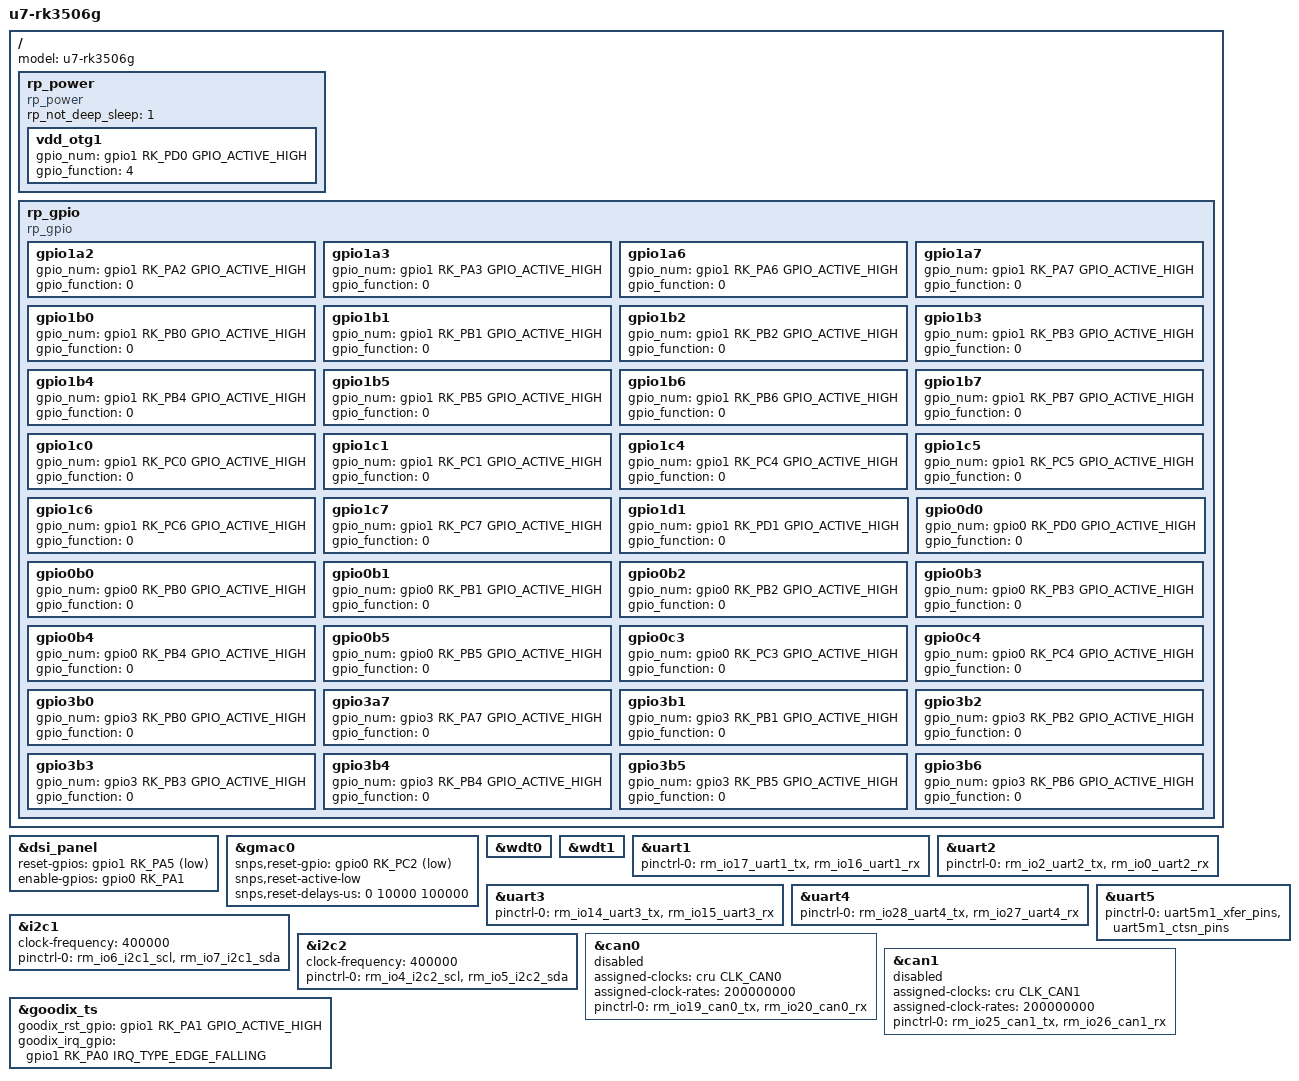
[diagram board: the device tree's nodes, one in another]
// SPDX-License-Identifier: (GPL-2.0+ OR MIT)
/*
 * Copyright (c) 2024 Rockchip Electronics Co., Ltd.
 */

/dts-v1/;
#include <dt-bindings/gpio/nca9555-gpio.h>

#include "rp-rk3506b-board.dtsi"

#include "rp-adc.dtsi"

#include "rp-usb2.0-otg0-typeA.dtsi"
#include "rp-usb2.0-host1-typeA.dtsi"

#include "rp-gmac0-100m.dtsi"
#include "rp-sdcard-mmc0.dtsi"

//#include "rp-lcd-mipi-7-1024-600.dtsi"
#include "rp-lcd-mipi-7-1024-600-lcdm012.dtsi"
//#include "rp-lcd-mipi0-8-800-1280-lcdm028T.dtsi"
// #include "rp-lcd-mipi0-10-800-1280-lcdm036J.dtsi"

/ {
    model = "u7-rk3506g";
	
    rp_power {
        status = "okay";
        compatible = "rp_power";
        rp_not_deep_sleep = <1>;

//#define GPIO_FUNCTION_OUTPUT 0
//#define GPIO_FUNCTION_INPUT 1
//#define GPIO_FUNCTION_IRQ 2
//#define GPIO_FUNCTION_FLASH 3
//#define GPIO_FUNCTION_OUTPUT_CTRL 4
        vdd_otg1 {
            gpio_num = <&gpio1 RK_PD0 GPIO_ACTIVE_HIGH>;
            gpio_function = <4>;
        };
    };
 
    rp_gpio {
        status = "okay";
        compatible = "rp_gpio";
        gpio1a2 {
            gpio_num = <&gpio1 RK_PA2 GPIO_ACTIVE_HIGH>;
            gpio_function = <0>;
        };
        
        gpio1a3 {
            gpio_num = <&gpio1 RK_PA3 GPIO_ACTIVE_HIGH>;
            gpio_function = <0>;
        };
        
        gpio1a6 {
            gpio_num = <&gpio1 RK_PA6 GPIO_ACTIVE_HIGH>;
            gpio_function = <0>;
        };
        
        gpio1a7 {
            gpio_num = <&gpio1 RK_PA7 GPIO_ACTIVE_HIGH>;
            gpio_function = <0>;
        };
        
        gpio1b0 {
            gpio_num = <&gpio1 RK_PB0 GPIO_ACTIVE_HIGH>;
            gpio_function = <0>;
        };
        
        gpio1b1 {
            gpio_num = <&gpio1 RK_PB1 GPIO_ACTIVE_HIGH>;
            gpio_function = <0>;
        };
        
        gpio1b2 {
            gpio_num = <&gpio1 RK_PB2 GPIO_ACTIVE_HIGH>;
            gpio_function = <0>;
        };
        
        gpio1b3 {
            gpio_num = <&gpio1 RK_PB3 GPIO_ACTIVE_HIGH>;
            gpio_function = <0>;
        };
        
        gpio1b4 {
            gpio_num = <&gpio1 RK_PB4 GPIO_ACTIVE_HIGH>;
            gpio_function = <0>;
        };
        
        gpio1b5 {
            gpio_num = <&gpio1 RK_PB5 GPIO_ACTIVE_HIGH>;
            gpio_function = <0>;
        };
        
        gpio1b6 {
            gpio_num = <&gpio1 RK_PB6 GPIO_ACTIVE_HIGH>;
            gpio_function = <0>;
        };
        
        gpio1b7 {
            gpio_num = <&gpio1 RK_PB7 GPIO_ACTIVE_HIGH>;
            gpio_function = <0>;
        };
        
        gpio1c0 {
            gpio_num = <&gpio1 RK_PC0 GPIO_ACTIVE_HIGH>;
            gpio_function = <0>;
        };
        
        gpio1c1 {
            gpio_num = <&gpio1 RK_PC1 GPIO_ACTIVE_HIGH>;
            gpio_function = <0>;
        };
        
        gpio1c4 {
            gpio_num = <&gpio1 RK_PC4 GPIO_ACTIVE_HIGH>;
            gpio_function = <0>;
        };
        
        gpio1c5 {
            gpio_num = <&gpio1 RK_PC5 GPIO_ACTIVE_HIGH>;
            gpio_function = <0>;
        };
        
        gpio1c6 {
            gpio_num = <&gpio1 RK_PC6 GPIO_ACTIVE_HIGH>;
            gpio_function = <0>;
        };
        
        gpio1c7 {
            gpio_num = <&gpio1 RK_PC7 GPIO_ACTIVE_HIGH>;
            gpio_function = <0>;
        };
        
        gpio1d1 {
            gpio_num = <&gpio1 RK_PD1 GPIO_ACTIVE_HIGH>;
            gpio_function = <0>;
        };
        
        gpio0d0 {
            gpio_num = <&gpio0 RK_PD0 GPIO_ACTIVE_HIGH>;
            gpio_function = <0>;
        };
        
        gpio0b0 {
            gpio_num = <&gpio0 RK_PB0 GPIO_ACTIVE_HIGH>;
            gpio_function = <0>;
        };
        
        gpio0b1 {
            gpio_num = <&gpio0 RK_PB1 GPIO_ACTIVE_HIGH>;
            gpio_function = <0>;
        };
        
        gpio0b2 {
            gpio_num = <&gpio0 RK_PB2 GPIO_ACTIVE_HIGH>;
            gpio_function = <0>;
        };
        
        gpio0b3 {
            gpio_num = <&gpio0 RK_PB3 GPIO_ACTIVE_HIGH>;
            gpio_function = <0>;
        };
        
        gpio0b4 {
            gpio_num = <&gpio0 RK_PB4 GPIO_ACTIVE_HIGH>;
            gpio_function = <0>;
        };
        
        gpio0b5 {
            gpio_num = <&gpio0 RK_PB5 GPIO_ACTIVE_HIGH>;
            gpio_function = <0>;
        };
        
        gpio0c3 {
            gpio_num = <&gpio0 RK_PC3 GPIO_ACTIVE_HIGH>;
            gpio_function = <0>;
        };
        
        gpio0c4 {
            gpio_num = <&gpio0 RK_PC4 GPIO_ACTIVE_HIGH>;
            gpio_function = <0>;
        };
           
        gpio3b0 {
            gpio_num = <&gpio3 RK_PB0 GPIO_ACTIVE_HIGH>;
            gpio_function = <0>;
        };
        
        gpio3a7 {
            gpio_num = <&gpio3 RK_PA7 GPIO_ACTIVE_HIGH>;
            gpio_function = <0>;
        };
        
        gpio3b1 {
            gpio_num = <&gpio3 RK_PB1 GPIO_ACTIVE_HIGH>;
            gpio_function = <0>;
        };
        
        gpio3b2 {
            gpio_num = <&gpio3 RK_PB2 GPIO_ACTIVE_HIGH>;
            gpio_function = <0>;
        };
        
        gpio3b3 {
            gpio_num = <&gpio3 RK_PB3 GPIO_ACTIVE_HIGH>;
            gpio_function = <0>;
        };
        
        gpio3b4 {
            gpio_num = <&gpio3 RK_PB4 GPIO_ACTIVE_HIGH>;
            gpio_function = <0>;
        };
        
        gpio3b5 {
            gpio_num = <&gpio3 RK_PB5 GPIO_ACTIVE_HIGH>;
            gpio_function = <0>;
        };
        
        gpio3b6 {
            gpio_num = <&gpio3 RK_PB6 GPIO_ACTIVE_HIGH>;
            gpio_function = <0>;
        };
    };
};

&dsi_panel {
    reset-gpios = <&gpio1 RK_PA5 GPIO_ACTIVE_LOW>;
    enable-gpios = <&gpio0 RK_PA1 GPIO_ACTIVE_HIGH>;
};

&gmac0 {
    status = "okay";
    snps,reset-gpio = <&gpio0 RK_PC2 GPIO_ACTIVE_LOW>;
    snps,reset-active-low;
    /* Reset time is 20ms, 100ms for rtl8211f */
    snps,reset-delays-us = <0 10000 100000>;	
};

&wdt0 {
    status = "okay";
};

&wdt1 {
    status = "okay";
};

// TTL
&uart1 {
    status = "okay";
    pinctrl-names = "default";
    pinctrl-0 = <&rm_io17_uart1_tx &rm_io16_uart1_rx>;	
};

// TTL
&uart2 {
    status = "okay";
    pinctrl-names = "default";
    pinctrl-0 = <&rm_io2_uart2_tx &rm_io0_uart2_rx>;      
};

// TTL
&uart3 {
    status = "okay";
    pinctrl-names = "default";
    pinctrl-0 = <&rm_io14_uart3_tx &rm_io15_uart3_rx>;
};

// TTL
&uart4 {
    status = "okay";
    pinctrl-names = "default";
    pinctrl-0 = <&rm_io28_uart4_tx &rm_io27_uart4_rx>;	    
};

// TTL
&uart5 {
    pinctrl-names = "default";
    pinctrl-0 = <&uart5m1_xfer_pins &uart5m1_ctsn_pins>;
    status = "okay";
};

&i2c1 {
    status = "okay";
    clock-frequency = <400000>;
    pinctrl-names = "default";
    pinctrl-0 = <&rm_io6_i2c1_scl &rm_io7_i2c1_sda>;
};

&i2c2 {
    status = "okay";
    clock-frequency = <400000>;
    pinctrl-names = "default";
    pinctrl-0 = <&rm_io4_i2c2_scl &rm_io5_i2c2_sda>;
};

// Has been configured as GPIO.
&can0 {
    status = "disabled";
    assigned-clocks = <&cru CLK_CAN0>;
    assigned-clock-rates = <200000000>;
    pinctrl-names = "default";
    pinctrl-0 = <&rm_io19_can0_tx &rm_io20_can0_rx>;
};

// Has been configured as GPIO.
&can1 {
    status = "disabled";
    assigned-clocks = <&cru CLK_CAN1>;
    assigned-clock-rates = <200000000>;  
    pinctrl-names = "default";
    pinctrl-0 = <&rm_io25_can1_tx &rm_io26_can1_rx>;
};

&goodix_ts {
    goodix_rst_gpio = <&gpio1 RK_PA1 GPIO_ACTIVE_HIGH>;
    goodix_irq_gpio = <&gpio1 RK_PA0 IRQ_TYPE_EDGE_FALLING>;
    //buzzer_gpio = <&gpio1 RK_PA2 GPIO_ACTIVE_LOW>; // 蜂鸣器IO
};
